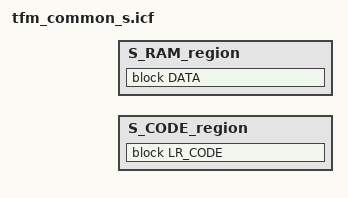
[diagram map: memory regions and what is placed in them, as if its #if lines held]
/*********** WARNING: This is an auto-generated file. Do not edit! ***********/

#include "region_defs.h"

define memory mem with size = 4G;

define region S_CODE_region     = mem:[from S_CODE_START size S_CODE_SIZE];
define region NS_CODE_region 	= mem:[from NS_PARTITION_START size NS_PARTITION_SIZE];
define region BL2_CODE_region 	= mem:[from BL2_CODE_START size BL2_CODE_SIZE];

define region S_RAM_region   	= mem:[from S_DATA_START size S_DATA_SIZE];
define region NS_RAM_region  	= mem:[from NS_DATA_START size NS_DATA_SIZE];
define region BL2_RAM_region  	= mem:[from BL2_DATA_START size BL2_DATA_SIZE];


define block ER_TFM_CODE          with fixed order, alignment = 8 {readonly section .intvec };

define block TFM_UNPRIV_CODE with alignment = 32 {
 	   ro object tfm_spm_services.o,
       ro object dummy_crypto_keys.o,
       ro object dummy_nv_counters.o,
       ro object dummy_boot_seed.o,
       ro object dummy_device_id.o,
       ro object platform_retarget_dev.o,
       ro object device_definition.o,
       section SFN,
	   ro object data_init.o,
	   ro object zero_init3.o,
	   ro object copy_init3.o,
		};
    /**** PSA RoT RO part (CODE + RODATA) start here */
    /*
     * This empty, zero long execution region is here to mark the start address
     * of PSA RoT code.
     */
define block TFM_PSA_CODE_START with alignment = 32, size = 0 { };

define block TFM_PRIV_CODE with alignment = 32 {
        ro object *,
    };

#ifdef TFM_PARTITION_AUDIT_LOG
define block TFM_SP_AUDIT_LOG with alignment = 32 {
        ro object *tfm_audit*,
    };
#endif /* TFM_PARTITION_AUDIT_LOG */



#ifdef TFM_PARTITION_PLATFORM
define block TFM_SP_PLATFORM with alignment = 32 {
        ro object *tfm_platform*,
    };
#endif /* TFM_PARTITION_PLATFORM */



#ifdef TFM_PARTITION_TEST_CORE
define block TFM_SP_CORE_TEST with alignment = 32 {
        ro object *tfm_ss_core_test.*,
    };
#endif /* TFM_PARTITION_TEST_CORE */

#ifdef TFM_PARTITION_TEST_SECURE_SERVICES
define block TFM_SP_SECURE_TEST_PARTITION with alignment = 32 {
        ro object *tfm_secure_client_service.*,
        ro object *test_framework*,
        ro object *uart_stdout.*,
        ro object *Driver_USART.*,
        ro object *arm_uart_drv.*,
        ro object *uart_pl011_drv.*,
        ro object *uart_cmsdk_drv*,
        ro object *secure_suites.*,
        ro object *attestation_s_interface_testsuite.*,
    };
#endif /* TFM_PARTITION_TEST_SECURE_SERVICES */

#ifdef TFM_PARTITION_TEST_CORE_IPC
define block TFM_SP_IPC_SERVICE_TEST with alignment = 32 {
        ro object *ipc_service_test.*,
    };
#endif /* TFM_PARTITION_TEST_CORE_IPC */

    /*
     * This empty, zero long execution region is here to mark the end address
     * of PSA RoT code.
     */
define block TFM_PSA_CODE_END with alignment = 32, size = 0 { };

    /**** APPLICATION RoT RO part (CODE + RODATA) start here */
    /*
     * This empty, zero long execution region is here to mark the start address
     * of APP RoT code.
     */
define block TFM_APP_CODE_START with alignment = 32, size = 0 { };

#ifdef TFM_PARTITION_TEST_CORE
define block TFM_SP_CORE_TEST_2 with alignment = 32 {
        ro object *tfm_ss_core_test_2.*,
    };
#endif /* TFM_PARTITION_TEST_CORE */

#ifdef TFM_PARTITION_TEST_CORE_IPC
define block TFM_SP_IPC_CLIENT_TEST with alignment = 32 {
        ro object *ipc_client_test.*,
    };
#endif /* TFM_PARTITION_TEST_CORE_IPC */

#ifdef TFM_ENABLE_IRQ_TEST
define block TFM_IRQ_TEST_1 with alignment = 32 {
        ro object *tfm_irq_test_service_1.*,
        ro object *timer_cmsdk*,
    };
#endif /* TFM_ENABLE_IRQ_TEST */

    /*
     * This empty, zero long execution region is here to mark the end address
     * of APP RoT code.
     */
define block TFM_APP_CODE_END with alignment = 32, size = 0 { };

    /* Shared area between BL2 and runtime to exchange data */
define block TFM_SHARED_DATA with alignment = 32, size = BOOT_TFM_SHARED_DATA_SIZE { };
define block ARM_LIB_STACK_MSP	  with alignment = 32, size = S_MSP_STACK_SIZE { };
define overlay STACK_DATA {block TFM_SHARED_DATA, block ARM_LIB_STACK_MSP};

/* PSP */
define block ARM_LIB_STACK with alignment = 32, size = S_PSP_STACK_SIZE { };

define block HEAP		  with alignment = 8, size = S_HEAP_SIZE { };

define block ER_TFM_PRIV_DATA          with alignment = 8 {readwrite};

#if !defined(TFM_PSA_API)
define block TFM_SECURE_STACK   with size = 0x2000, alignment = 128 {};
#endif /* !defined(TFM_PSA_API) */

define block TFM_UNPRIV_DATA with alignment = 32 {
       rw object tfm_spm_services.o,
       rw object dummy_crypto_keys.o,
       rw object dummy_nv_counters.o,
       rw object dummy_boot_seed.o,
       rw object dummy_device_id.o,
       rw object platform_retarget_dev.o,
       rw object device_definition.o,
       };

    /**** PSA RoT DATA start here */
    /*
     * This empty, zero long execution region is here to mark the start address
     * of PSA RoT RW and Stack.
     */
define block TFM_PSA_RW_STACK_START with alignment = 32, size = 0 { };

#if defined (TFM_PSA_API)
define block TFM_SP_STORAGE_STACK with alignment = 128, size = 0xA00 { };
#endif

#if defined (TFM_PSA_API)
define block TFM_SP_ITS_STACK with alignment = 128, size = 0xA00 { };
#endif


#ifdef TFM_PARTITION_AUDIT_LOG
define block TFM_SP_AUDIT_LOG_DATA with alignment = 32 {
        rw object *tfm_audit*,
};

#if defined (TFM_PSA_API)
define block TFM_SP_AUDIT_LOG_STACK with alignment = 128, size = 0 { };
#endif
#endif /* TFM_PARTITION_AUDIT_LOG */



#if defined (TFM_PSA_API)
define block TFM_SP_CRYPTO_STACK with alignment = 128, size = 0x2000 { };
#endif

#ifdef TFM_PARTITION_PLATFORM
define block TFM_SP_PLATFORM_DATA with alignment = 32 {
        rw object *tfm_platform*,
};

#if defined (TFM_PSA_API)
define block TFM_SP_PLATFORM_STACK with alignment = 128, size = 0 { };
#endif
#endif /* TFM_PARTITION_PLATFORM */


#if defined (TFM_PSA_API)
define block TFM_SP_INITIAL_ATTESTATION_STACK with alignment = 128, size = 0x0A00 { };
#endif

#ifdef TFM_PARTITION_TEST_CORE
define block TFM_SP_CORE_TEST_DATA with alignment = 32 {
        rw object *tfm_ss_core_test.*,
};

#if defined (TFM_PSA_API)
define block TFM_SP_CORE_TEST_STACK with alignment = 128, size = 0x0300 { };
#endif
#endif /* TFM_PARTITION_TEST_CORE */

#ifdef TFM_PARTITION_TEST_SECURE_SERVICES
define block TFM_SP_SECURE_TEST_PARTITION_DATA with alignment = 32 {
        rw object *tfm_secure_client_service.*,
        rw object *test_framework*,
        rw object *uart_stdout.*,
        rw object *Driver_USART.*,
        rw object *arm_uart_drv.*,
        rw object *uart_pl011_drv.*,
        rw object *uart_cmsdk_drv*,
        rw object *secure_suites.*,
        rw object *attestation_s_interface_testsuite.*,
};

#if defined (TFM_PSA_API)
define block TFM_SP_SECURE_TEST_PARTITION_STACK with alignment = 128, size = 0x0C00 { };
#endif
#endif /* TFM_PARTITION_TEST_SECURE_SERVICES */

#ifdef TFM_PARTITION_TEST_CORE_IPC
define block TFM_SP_IPC_SERVICE_TEST_DATA with alignment = 32 {
        rw object *ipc_service_test.*,
};

#if defined (TFM_PSA_API)
define block TFM_SP_IPC_SERVICE_TEST_STACK with alignment = 128, size = 0x0220 { };
#endif
#endif /* TFM_PARTITION_TEST_CORE_IPC */

    /*
     * This empty, zero long execution region is here to mark the end address
     * of PSA RoT RW and Stack.
     */
define block TFM_PSA_RW_STACK_END with alignment = 32, size = 0x0 { };

    /**** APP RoT DATA start here */
    /*
     * This empty, zero long execution region is here to mark the start address
     * of APP RoT RW and Stack.
     */
define block TFM_APP_RW_STACK_START with alignment = 32, size = 0 { };

#ifdef TFM_PARTITION_TEST_CORE
define block TFM_SP_CORE_TEST_2_DATA with alignment = 32 {
        rw object *tfm_ss_core_test_2.*,
    };

#if defined (TFM_PSA_API)
define block TFM_SP_CORE_TEST_2_STACK with alignment = 128, size = 0x0200 { };
#endif
#endif /* TFM_PARTITION_TEST_CORE */

#ifdef TFM_PARTITION_TEST_CORE_IPC
define block TFM_SP_IPC_CLIENT_TEST_DATA with alignment = 32 {
        rw object *ipc_client_test.*,
    };

#if defined (TFM_PSA_API)
define block TFM_SP_IPC_CLIENT_TEST_STACK with alignment = 128, size = 0x0220 { };
#endif
#endif /* TFM_PARTITION_TEST_CORE_IPC */

#ifdef TFM_ENABLE_IRQ_TEST
define block TFM_IRQ_TEST_1_DATA with alignment = 32 {
        rw object *tfm_irq_test_service_1.*,
        rw object *timer_cmsdk*,
    };

#if defined (TFM_PSA_API)
define block TFM_IRQ_TEST_1_STACK with alignment = 128, size = 0x0400 { };
#endif
#endif /* TFM_ENABLE_IRQ_TEST */

    /*
     * This empty, zero long execution region is here to mark the end address
     * of APP RoT RW and Stack.
     */
define block TFM_APP_RW_STACK_END with alignment = 32, size = 0 { };

define block SRAM_WATERMARK with size = 0 { };

define block LR_CODE with fixed order {
       block ER_TFM_CODE,
       block TFM_UNPRIV_CODE,
       block TFM_PSA_CODE_START,

       block TFM_PRIV_CODE,
#ifdef TFM_PARTITION_AUDIT_LOG
       block TFM_SP_AUDIT_LOG,
#endif /* TFM_PARTITION_AUDIT_LOG */
#ifdef TFM_PARTITION_PLATFORM
       block TFM_SP_PLATFORM,
#endif /* TFM_PARTITION_PLATFORM */
#ifdef TFM_PARTITION_TEST_CORE
       block TFM_SP_CORE_TEST,
#endif /* TFM_PARTITION_TEST_CORE */
#ifdef TFM_PARTITION_TEST_SECURE_SERVICES
       block TFM_SP_SECURE_TEST_PARTITION,
#endif /* TFM_PARTITION_TEST_SECURE_SERVICES */
#ifdef TFM_PARTITION_TEST_CORE_IPC
       block TFM_SP_IPC_SERVICE_TEST,
#endif /* TFM_PARTITION_TEST_CORE_IPC */

       block TFM_PSA_CODE_END,
    /**** APPLICATION RoT RO part (CODE + RODATA) start here */
    /*
     * This empty, zero long execution region is here to mark the start address
     * of APP RoT code.
     */
       block TFM_APP_CODE_START,
#ifdef TFM_PARTITION_TEST_CORE
       block TFM_SP_CORE_TEST_2,
#endif /* TFM_PARTITION_TEST_CORE */

#ifdef TFM_PARTITION_TEST_CORE_IPC
       block TFM_SP_IPC_CLIENT_TEST,
#endif /* TFM_PARTITION_TEST_CORE_IPC */

#ifdef TFM_ENABLE_IRQ_TEST
       block TFM_IRQ_TEST_1,
#endif /* TFM_ENABLE_IRQ_TEST */

       block TFM_APP_CODE_END,
};

do not initialize  { section .noinit };
initialize by copy { readwrite };
if (isdefinedsymbol(__USE_DLIB_PERTHREAD))
{
  // Required in a multi-threaded application
  initialize by copy { section __DLIB_PERTHREAD };
}

place in S_CODE_region         { block LR_CODE };

define block DATA with fixed order {
       overlay STACK_DATA,
       block ARM_LIB_STACK,
       block HEAP,
       block ER_TFM_PRIV_DATA,

#if !defined(TFM_PSA_API)
       block TFM_SECURE_STACK,
#endif /* !defined(TFM_PSA_API) */

       block TFM_UNPRIV_DATA,
    /**** PSA RoT DATA start here */
    /*
     * This empty, zero long execution region is here to mark the start address
     * of PSA RoT RW and Stack.
     */
       block TFM_PSA_RW_STACK_START,

       
#if defined (TFM_PSA_API)
       block TFM_SP_STORAGE_STACK,
#endif

#if defined (TFM_PSA_API)
       block TFM_SP_ITS_STACK,
#endif

#ifdef TFM_PARTITION_AUDIT_LOG
       block TFM_SP_AUDIT_LOG_DATA,

#endif /* TFM_PARTITION_AUDIT_LOG */

#if defined (TFM_PSA_API)
       block TFM_SP_CRYPTO_STACK,
#endif

#ifdef TFM_PARTITION_PLATFORM
       block TFM_SP_PLATFORM_DATA,

#endif /* TFM_PARTITION_PLATFORM */

#if defined (TFM_PSA_API)
       block TFM_SP_INITIAL_ATTESTATION_STACK,
#endif

#ifdef TFM_PARTITION_TEST_CORE
       block TFM_SP_CORE_TEST_DATA,

#if defined (TFM_PSA_API)
       block TFM_SP_CORE_TEST_STACK,
#endif
#endif /* TFM_PARTITION_TEST_CORE */

#ifdef TFM_PARTITION_TEST_SECURE_SERVICES
       block TFM_SP_SECURE_TEST_PARTITION_DATA,

#if defined (TFM_PSA_API)
       block TFM_SP_SECURE_TEST_PARTITION_STACK,
#endif
#endif /* TFM_PARTITION_TEST_SECURE_SERVICES */

#ifdef TFM_PARTITION_TEST_CORE_IPC
       block TFM_SP_IPC_SERVICE_TEST_DATA,

#if defined (TFM_PSA_API)
       block TFM_SP_IPC_SERVICE_TEST_STACK,
#endif
#endif /* TFM_PARTITION_TEST_CORE_IPC */

    /*
     * This empty, zero long execution region is here to mark the end address
     * of PSA RoT RW and Stack.
     */
       block TFM_PSA_RW_STACK_END,
       block TFM_APP_RW_STACK_START,
#ifdef TFM_PARTITION_TEST_CORE
       block TFM_SP_CORE_TEST_2_DATA,

#if defined (TFM_PSA_API)
       block TFM_SP_CORE_TEST_2_STACK,
#endif
#endif /* TFM_PARTITION_TEST_CORE */

#ifdef TFM_PARTITION_TEST_CORE_IPC
       block TFM_SP_IPC_CLIENT_TEST_DATA,

#if defined (TFM_PSA_API)
       block TFM_SP_IPC_CLIENT_TEST_STACK,
#endif
#endif /* TFM_PARTITION_TEST_CORE_IPC */

#ifdef TFM_ENABLE_IRQ_TEST
       block TFM_IRQ_TEST_1_DATA,

#if defined (TFM_PSA_API)
       block TFM_IRQ_TEST_1_STACK,
#endif
#endif /* TFM_ENABLE_IRQ_TEST */

    /*
     * This empty, zero long execution region is here to mark the end address
     * of APP RoT RW and Stack.
     */
       block TFM_APP_RW_STACK_END,
       block SRAM_WATERMARK
};

#if !TFM_MULTI_CORE_TOPOLOGY
    /*
     * Place the CMSE Veneers (containing the SG instruction) in a separate
     * 32 bytes aligned region so that the SAU can be programmed to
     * just set this region as Non-Secure Callable.
     */
define block LR_VENEER with alignment = 0x20, size = CMSE_VENEER_REGION_SIZE {section Veneer$$CMSE};
place at address CMSE_VENEER_REGION_START {block LR_VENEER};
#endif

    /* Reserved place for NS application.
     * No code will be placed here, just address of this region is used in the
     * secure code to configure certain HW components. This generates an empty
     * execution region description warning during linking.
     */
define block LR_NS_PARTITION with size = NS_PARTITION_SIZE { };
place at address NS_PARTITION_START { block LR_NS_PARTITION };

#ifdef BL2
    /* Reserved place for new image in case of firmware upgrade.
     * No code will be placed here, just address of this region is used in the
     * secure code to configure certain HW components. This generates an empty
     * execution region description warning during linking.
     */
define block LR_SECONDARY_PARTITION with size = SECONDARY_PARTITION_SIZE { };
place at address SECONDARY_PARTITION_START { block LR_SECONDARY_PARTITION };
#endif /* BL2 */

place in S_RAM_region          { block DATA };
